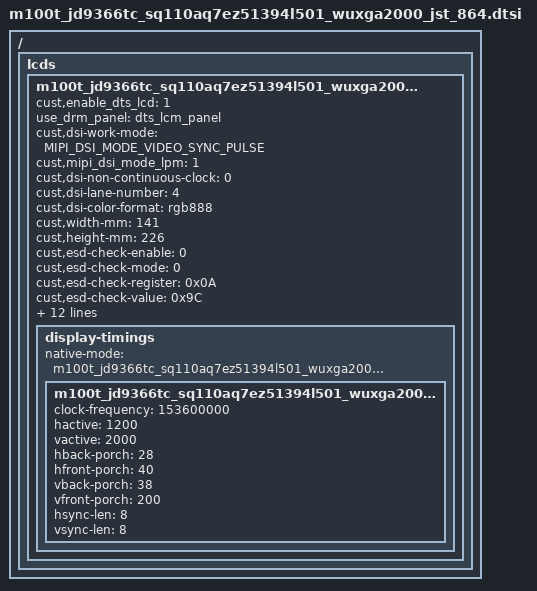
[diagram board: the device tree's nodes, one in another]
#include <dt-bindings/display/cust_drm.h>

/ {
	fragment {
		target-path = "/";
		__overlay__ {
			lcds {
				m100t_jd9366tc_sq110aq7ez51394l501_wuxga2000_jst_864: m100t_jd9366tc_sq110aq7ez51394l501_wuxga2000_jst_864 {

					cust,enable_dts_lcd=<1>; //use lcd dts
					use_drm_panel="dts_lcm_panel";
					cust,dsi-work-mode = <MIPI_DSI_MODE_VIDEO_SYNC_PULSE>;
					cust,mipi_dsi_mode_lpm=<1>;
					cust,dsi-non-continuous-clock=<0>;
					cust,dsi-lane-number = <4>;
					cust,dsi-color-format = "rgb888";

					//cust,lcm_phy_size=<1036>;
					cust,width-mm = <141>;
					cust,height-mm = <226>;

					cust,esd-check-enable = <0>;
					cust,esd-check-mode = <0>;
					cust,esd-check-register = <0x0A>;
					cust,esd-check-value = <0x9C>;

					/*<cust_gpio_type enable_level delay>*/
					/*cust,power-on-sequence = <CUST_GPIO_LCM_1V8 HIGH 10>,
											<CUST_GPIO_BIAS_POS HIGH 1>, 
											<CUST_GPIO_BIAS_NEG HIGH 20>,
											<CUST_GPIO_TP_RST LOW 1>,
											<CUST_GPIO_TP_RST HIGH 1>,
											<CUST_GPIO_LCM_RST HIGH 10>,
											<CUST_GPIO_LCM_RST LOW 2>,
											<CUST_GPIO_LCM_RST HIGH 5>;

					cust,power-on-sequence_after_cmd=<CUST_GPIO_BIAS_EN HIGH 0>;*/

					cust,power-off-sequence = <CUST_GPIO_TP_RST LOW 0>;
											
					/*cust,power-off-sequence_before_cmd= <CUST_GPIO_BIAS_EN LOW 0>;*/
					
					/*dely SizeH SizeL Cmd Data */
						cust,initial-command = [
						00 02 30 01 
						00 05 78 49 61 02 00 
						00 02 30 02 
						00 02 31 22 
						00 02 32 10 
						00 02 33 36 
						00 02 3d 42 
						00 02 3f 61 
						00 02 42 82 
						00 02 43 70 
						00 02 44 21 
						00 02 49 82 
						00 02 4a 3f 
						00 0d 41 00 00 00 00 00 00 0c 0c 00 00 00 00 
						00 0c 5a 23 23 23 23 23 23 23 19 23 21 20 
						00 0c 5b 17 15 13 11 0f 0d 0b 09 01 23 23 
						00 0c 5c 23 23 23 23 23 23 23 18 23 21 20 
						00 0c 5d 16 14 12 10 0e 0c 0a 08 00 23 23 
						00 03 4e ff ff 
						00 03 50 01 01 
						00 03 55 00 00 
						00 03 56 00 00 
						00 04 6f 00 04 00 
						00 04 70 00 04 00 
						00 04 71 ff ff 3f 
						00 04 72 ff ff 3f 
						00 02 30 05 
						00 02 31 00 
						00 04 40 6f 39 39 
						00 02 30 07 
						00 02 31 c0 
						00 02 30 02 
						00 02 30 08 
						00 02 40 3d 
						00 02 41 3d 
						00 02 42 0f 
						00 02 47 0a 
						00 02 48 0c 
						00 02 4a 17 
						00 02 4b 1a 
						00 02 4c a0 
						00 02 4e a0 
						00 02 50 0a 
						00 02 52 83 
						00 02 5a b0 
						00 02 5b d0 
						00 02 5c 74 
						00 02 62 04 
						00 02 65 5f 
						00 02 7e 0f 
						00 02 5e 00 
						00 02 73 01 
						00 02 30 0a 
						00 02 32 3f 
						00 02 3f 50 
						00 02 42 31 
						00 02 43 00 
						00 02 49 03 
						00 02 30 0b 
						00 03 33 00 54 
						00 03 3c 00 92 
						00 02 43 ab 
						00 02 44 2b 
						00 06 3e 00 00 08 0d 13 
						00 0f 3f 1a 30 36 3d 39 56 5e 67 7a 7c 88 95 a5 a3 
						00 0a 40 50 58 5f 65 00 00 08 0d 13 
						00 0f 41 1a 30 36 3d 39 56 5e 67 7a 7c 88 95 a5 a3 
						00 05 42 50 58 70 73 
						00 02 45 59 
						00 02 46 45 
						00 02 48 7e 
						00 02 49 1f 
						00 02 4a 1a 
						00 02 4e 0a 
						00 02 4f 96 
						00 02 50 50 
						00 02 5a 18 
						00 02 5b 72 
						00 02 60 13 
						00 02 61 3f 
						00 02 67 14 
						00 02 30 0c 
						00 02 4a ab 
						00 02 4b d3 
						00 02 32 62 
						00 02 42 34 
						00 02 5e 00 
						00 02 6a 7f 
						00 02 62 41 
						00 02 30 0d 
						00 02 4c 74 
						00 02 30 08 
						00 02 52 c3 
						00 02 54 20 
						00 02 30 08 
						00 02 30 00 
						00 02 11 00 
						00 02 29 00 
						00 02 35 00 
						00 02 30 0c 
						00 02 4a ab 
						00 02 4b d3 
						00 02 30 00
						];
					cust,sleep-in-command = [
						0A 01 28 
						78 01 10
						00 02 30 0B 
						00 02 31 01
						00 02 30 00
						];
					cust,sleep-out-command = [
						78 01 11
						64 01 29
						];

					cust,pll_clk = <550>;
					cust,data_rate = <1100>;
					cust,rotate = <1>;
					cust,ssc_enable = <0>;
					cust,fps = <60>;

					display-timings {
						native-mode = <&m100t_jd9366tc_sq110aq7ez51394l501_wuxga2000_jst_864_timing>;

						m100t_jd9366tc_sq110aq7ez51394l501_wuxga2000_jst_864_timing: timing0 {
							clock-frequency = <153600000>; /*no need to modify,but can`t delete*/
							hactive = <1200>;
							vactive = <2000>;
							hback-porch = <28>;
							hfront-porch = <40>;
							vback-porch = <38>;
							vfront-porch = <200>;
							hsync-len = <8>;
							vsync-len = <8>;
						};
					};
				};
			};
		};
	};
};

